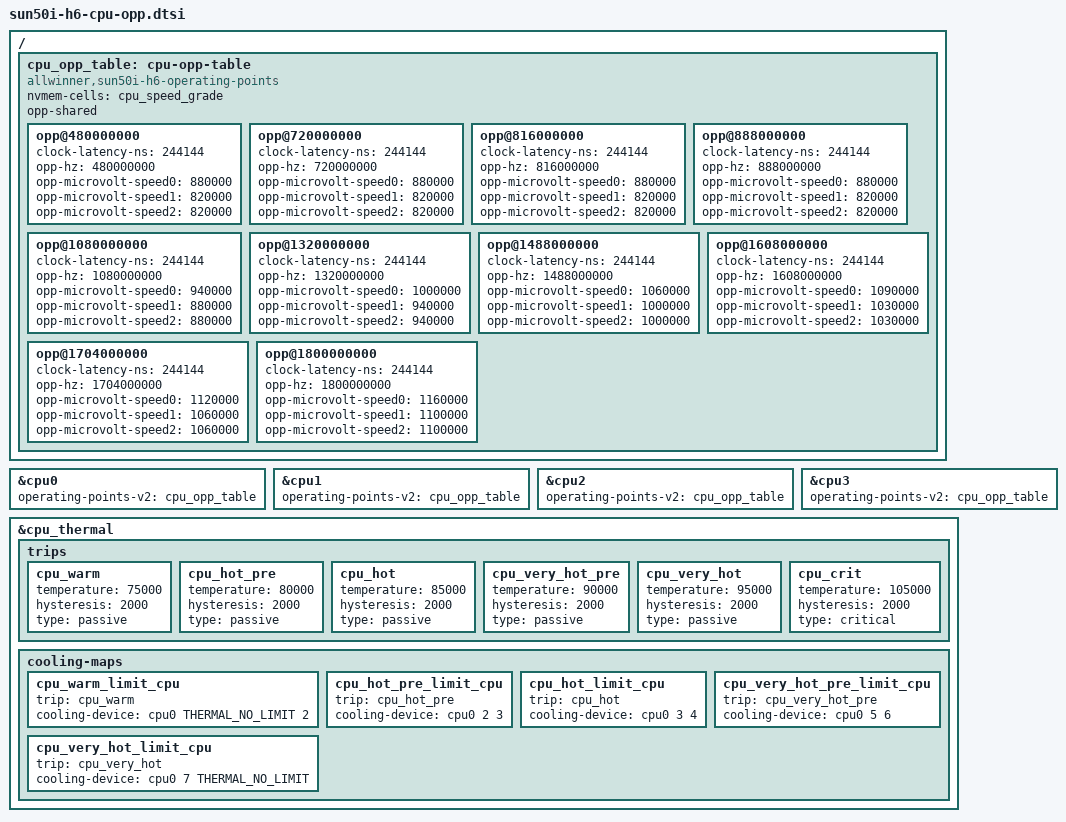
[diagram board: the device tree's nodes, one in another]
// SPDX-License-Identifier: (GPL-2.0+ OR MIT)
// Copyright (C) 2020 Ondrej Jirman <megous@megous.com>
// Copyright (C) 2020 Clément Péron <peron.clem@gmail.com>
// Copyright (C) 2020 Igor Pecovnik <igor@armbian.com>

/ {
	cpu_opp_table: cpu-opp-table {
		compatible = "allwinner,sun50i-h6-operating-points";
		nvmem-cells = <&cpu_speed_grade>;
		opp-shared;

		opp@480000000 {
			clock-latency-ns = <244144>; /* 8 32k periods */
			opp-hz = /bits/ 64 <480000000>;

			opp-microvolt-speed0 = <880000>;
			opp-microvolt-speed1 = <820000>;
			opp-microvolt-speed2 = <820000>;
		};

		opp@720000000 {
			clock-latency-ns = <244144>; /* 8 32k periods */
			opp-hz = /bits/ 64 <720000000>;

			opp-microvolt-speed0 = <880000>;
			opp-microvolt-speed1 = <820000>;
			opp-microvolt-speed2 = <820000>;
		};

		opp@816000000 {
			clock-latency-ns = <244144>; /* 8 32k periods */
			opp-hz = /bits/ 64 <816000000>;

			opp-microvolt-speed0 = <880000>;
			opp-microvolt-speed1 = <820000>;
			opp-microvolt-speed2 = <820000>;
		};

		opp@888000000 {
			clock-latency-ns = <244144>; /* 8 32k periods */
			opp-hz = /bits/ 64 <888000000>;

			opp-microvolt-speed0 = <880000>;
			opp-microvolt-speed1 = <820000>;
			opp-microvolt-speed2 = <820000>;
		};

		opp@1080000000 {
			clock-latency-ns = <244144>; /* 8 32k periods */
			opp-hz = /bits/ 64 <1080000000>;

			opp-microvolt-speed0 = <940000>;
			opp-microvolt-speed1 = <880000>;
			opp-microvolt-speed2 = <880000>;
		};

		opp@1320000000 {
			clock-latency-ns = <244144>; /* 8 32k periods */
			opp-hz = /bits/ 64 <1320000000>;

			opp-microvolt-speed0 = <1000000>;
			opp-microvolt-speed1 = <940000>;
			opp-microvolt-speed2 = <940000>;
		};

		opp@1488000000 {
			clock-latency-ns = <244144>; /* 8 32k periods */
			opp-hz = /bits/ 64 <1488000000>;

			opp-microvolt-speed0 = <1060000>;
			opp-microvolt-speed1 = <1000000>;
			opp-microvolt-speed2 = <1000000>;
		};

		opp@1608000000 {
			clock-latency-ns = <244144>; /* 8 32k periods */
			opp-hz = /bits/ 64 <1608000000>;

			opp-microvolt-speed0 = <1090000>;
			opp-microvolt-speed1 = <1030000>;
			opp-microvolt-speed2 = <1030000>;
		};

		opp@1704000000 {
			clock-latency-ns = <244144>; /* 8 32k periods */
			opp-hz = /bits/ 64 <1704000000>;

			opp-microvolt-speed0 = <1120000>;
			opp-microvolt-speed1 = <1060000>;
			opp-microvolt-speed2 = <1060000>;
		};

		opp@1800000000 {
			clock-latency-ns = <244144>; /* 8 32k periods */
			opp-hz = /bits/ 64 <1800000000>;

			opp-microvolt-speed0 = <1160000>;
			opp-microvolt-speed1 = <1100000>;
			opp-microvolt-speed2 = <1100000>;
		};
	};
};

&cpu0 {
	operating-points-v2 = <&cpu_opp_table>;
	#cooling-cells = <2>;
};

&cpu1 {
	operating-points-v2 = <&cpu_opp_table>;
	#cooling-cells = <2>;
};

&cpu2 {
	operating-points-v2 = <&cpu_opp_table>;
	#cooling-cells = <2>;
};

&cpu3 {
	operating-points-v2 = <&cpu_opp_table>;
	#cooling-cells = <2>;
};

&cpu_thermal {
	trips {
		cpu_warm: cpu_warm {
			temperature = <75000>;
			hysteresis = <2000>;
			type = "passive";
		};

		cpu_hot_pre: cpu_hot_pre {
			temperature = <80000>;
			hysteresis = <2000>;
			type = "passive";
		};
 
		cpu_hot: cpu_hot {
			temperature = <85000>;
			hysteresis = <2000>;
			type = "passive";
		};

		cpu_very_hot_pre: cpu_very_hot_pre {
			temperature = <90000>;
			hysteresis = <2000>;
			type = "passive";
		};

		cpu_very_hot: cpu_very_hot {
			temperature = <95000>;
			hysteresis = <2000>;
			type = "passive";
		};

		cpu_crit: cpu_crit {
			temperature = <105000>;
			hysteresis = <2000>;
			type = "critical";
		};
	};

	cooling-maps {
		cpu_warm_limit_cpu {
			trip = <&cpu_warm>;
			cooling-device = <&cpu0 THERMAL_NO_LIMIT 2>;
		};

		cpu_hot_pre_limit_cpu {
			trip = <&cpu_hot_pre>;
			cooling-device = <&cpu0 2 3>;
		};

		cpu_hot_limit_cpu {
			trip = <&cpu_hot>;
			cooling-device = <&cpu0 3 4>;
		};
	
		cpu_very_hot_pre_limit_cpu {
			trip = <&cpu_very_hot_pre>;
			cooling-device = <&cpu0 5 6>;
		};
	
		cpu_very_hot_limit_cpu {
			trip = <&cpu_very_hot>;
			cooling-device = <&cpu0 7 THERMAL_NO_LIMIT>;
		};
	};
};
